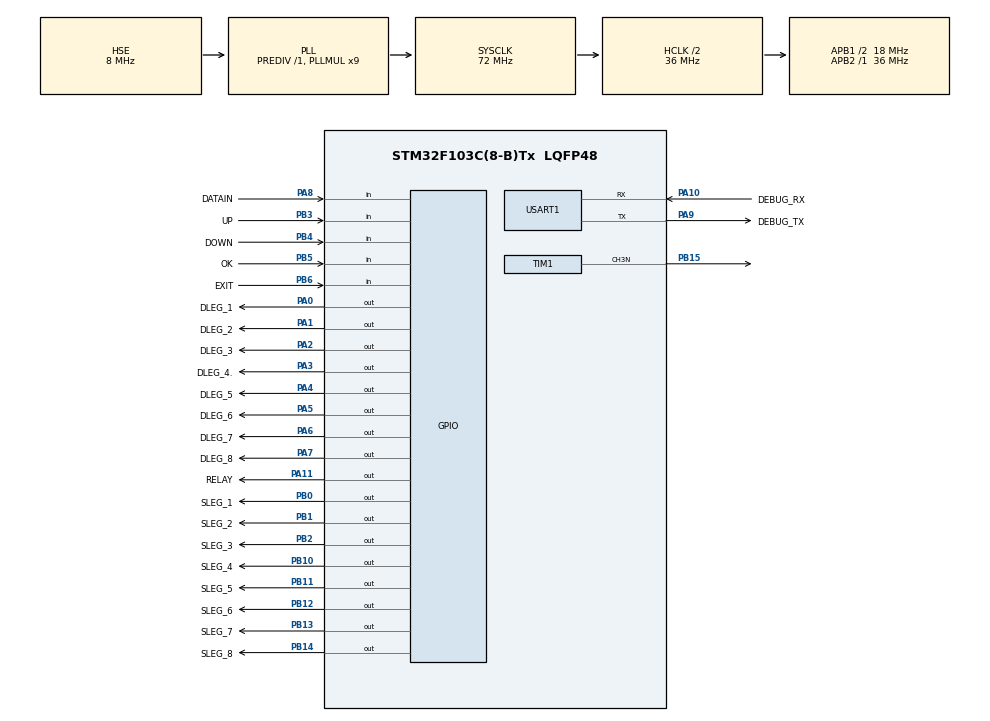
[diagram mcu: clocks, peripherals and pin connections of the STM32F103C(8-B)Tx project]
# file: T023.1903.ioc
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Mcu.Family=STM32F1
Mcu.Name=STM32F103C(8-B)Tx
Mcu.Package=LQFP48
NVIC.PriorityGroup=NVIC_PRIORITYGROUP_4
NVIC.TIM4_IRQn=true\:0\:0\:false\:false\:true\:true\:true
PA0-WKUP.GPIO_Label=DLEG_1
PA0-WKUP.Signal=GPIO_Output
PA1.GPIO_Label=DLEG_2
PA1.Signal=GPIO_Output
PA10.GPIO_Label=DEBUG_RX
PA10.Mode=Asynchronous
PA10.Signal=USART1_RX
PA11.GPIO_Label=RELAY
PA11.Signal=GPIO_Output
PA13.Mode=Serial_Wire
PA13.Signal=SYS_JTMS-SWDIO
PA14.Mode=Serial_Wire
PA14.Signal=SYS_JTCK-SWCLK
PA2.GPIO_Label=DLEG_3
PA2.Signal=GPIO_Output
PA3.GPIO_Label=DLEG_4.
PA3.Signal=GPIO_Output
PA4.GPIO_Label=DLEG_5
PA4.Signal=GPIO_Output
PA5.GPIO_Label=DLEG_6
PA5.Signal=GPIO_Output
PA6.GPIO_Label=DLEG_7
PA6.Signal=GPIO_Output
PA7.GPIO_Label=DLEG_8
PA7.Signal=GPIO_Output
PA8.GPIO_Label=DATAIN
PA8.Signal=GPIO_Input
PA9.GPIO_Label=DEBUG_TX
PA9.Mode=Asynchronous
PA9.Signal=USART1_TX
PB0.GPIO_Label=SLEG_1
PB0.Signal=GPIO_Output
PB1.GPIO_Label=SLEG_2
PB1.Signal=GPIO_Output
PB10.GPIO_Label=SLEG_4
PB10.Signal=GPIO_Output
PB11.GPIO_Label=SLEG_5
PB11.Signal=GPIO_Output
PB12.GPIO_Label=SLEG_6
PB12.Signal=GPIO_Output
PB13.GPIO_Label=SLEG_7
PB13.Signal=GPIO_Output
PB14.GPIO_Label=SLEG_8
PB14.Signal=GPIO_Output
PB15.Mode=PWM Generation3 CH3N
PB15.Signal=TIM1_CH3N
PB2.GPIO_Label=SLEG_3
PB2.Signal=GPIO_Output
PB3.GPIO_Label=UP
PB3.Signal=GPIO_Input
PB4.GPIO_Label=DOWN
PB4.Signal=GPIO_Input
PB5.GPIO_Label=OK
PB5.Signal=GPIO_Input
PB6.GPIO_Label=EXIT
PB6.Signal=GPIO_Input
PD0-OSC_IN.Mode=HSE-External-Oscillator
PD0-OSC_IN.Signal=RCC_OSC_IN
PD1-OSC_OUT.Mode=HSE-External-Oscillator
PD1-OSC_OUT.Signal=RCC_OSC_OUT
ProjectManager.HeapSize=0x200
ProjectManager.StackSize=0x400
ProjectManager.TargetToolchain=MDK-ARM V5
RCC.AHBCLKDivider=RCC_SYSCLK_DIV2
RCC.AHBFreq_Value=36000000
RCC.APB1CLKDivider=RCC_HCLK_DIV2
RCC.APB1Freq_Value=18000000
RCC.APB1TimFreq_Value=36000000
RCC.APB2Freq_Value=36000000
RCC.APB2TimFreq_Value=36000000
RCC.HCLKFreq_Value=36000000
RCC.PLLMUL=RCC_PLL_MUL9
RCC.PLLSourceVirtual=RCC_PLLSOURCE_HSE
RCC.SYSCLKFreq_VALUE=72000000
RCC.SYSCLKSource=RCC_SYSCLKSOURCE_PLLCLK
RCC.USBFreq_Value=72000000
TIM1.Channel-PWM\ Generation3\ CH3N=TIM_CHANNEL_3
TIM1.OCFastMode_PWM-PWM\ Generation3\ CH3N=TIM_OCFAST_ENABLE
TIM1.Period=999
TIM1.Prescaler=35
TIM4.Period=99
TIM4.Prescaler=179
USART1.VirtualMode=VM_ASYNC
VP_TIM1_VS_ClockSourceINT.Mode=Internal
VP_TIM4_VS_ClockSourceINT.Mode=Internal
board=custom

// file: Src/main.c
/* USER CODE BEGIN Header */
/**
  ******************************************************************************
  * @file           : main.c
  * @brief          : Main program body
  ******************************************************************************
  * @attention
  *
  * <h2><center>&copy; Copyright (c) 2019 STMicroelectronics.
  * All rights reserved.</center></h2>
  *
  * This software component is licensed by ST under BSD 3-Clause license,
  * the "License"; You may not use this file except in compliance with the
  * License. You may obtain a copy of the License at:
  *                        opensource.org/licenses/BSD-3-Clause
  *
  ******************************************************************************
  */
/* USER CODE END Header */

#include "main.h"
#include "tim.h"
#include "usart.h"
#include "gpio.h"

/* USER CODE BEGIN Includes */
#include "app.h"
/* USER CODE END Includes */

/* USER CODE BEGIN PV */
/* Private variables ---------------------------------------------------------*/

/* USER CODE END PV */

void SystemClock_Config(void);
/* USER CODE BEGIN PFP */
/* Private function prototypes -----------------------------------------------*/

/* USER CODE END PFP */

int main(void)
{

  /* MCU Configuration--------------------------------------------------------*/

  /* Reset of all peripherals, Initializes the Flash interface and the Systick. */
  HAL_Init();

  /* Configure the system clock */
  SystemClock_Config();

  /* Initialize all configured peripherals */
  MX_GPIO_Init();
  MX_TIM1_Init();
  MX_USART1_UART_Init();
  MX_TIM4_Init();
  /* USER CODE BEGIN 2 */
  App_Init();
  /* USER CODE END 2 */

  /* Infinite loop */
  while (1)
  {

    /* USER CODE BEGIN 3 */
    App_Step();
  }
  /* USER CODE END 3 */
}

void SystemClock_Config(void)
{
  RCC_OscInitTypeDef RCC_OscInitStruct = {0};
  RCC_ClkInitTypeDef RCC_ClkInitStruct = {0};

  /** Initializes the CPU, AHB and APB busses clocks
  */
  RCC_OscInitStruct.OscillatorType = RCC_OSCILLATORTYPE_HSE;
  RCC_OscInitStruct.HSEState = RCC_HSE_ON;
  RCC_OscInitStruct.HSEPredivValue = RCC_HSE_PREDIV_DIV1;
  RCC_OscInitStruct.HSIState = RCC_HSI_ON;
  RCC_OscInitStruct.PLL.PLLState = RCC_PLL_ON;
  RCC_OscInitStruct.PLL.PLLSource = RCC_PLLSOURCE_HSE;
  RCC_OscInitStruct.PLL.PLLMUL = RCC_PLL_MUL9;
  if (HAL_RCC_OscConfig(&RCC_OscInitStruct) != HAL_OK)
  {
    Error_Handler();
  }
  /** Initializes the CPU, AHB and APB busses clocks
  */
  RCC_ClkInitStruct.ClockType = RCC_CLOCKTYPE_HCLK|RCC_CLOCKTYPE_SYSCLK
                              |RCC_CLOCKTYPE_PCLK1|RCC_CLOCKTYPE_PCLK2;
  RCC_ClkInitStruct.SYSCLKSource = RCC_SYSCLKSOURCE_PLLCLK;
  RCC_ClkInitStruct.AHBCLKDivider = RCC_SYSCLK_DIV2;
  RCC_ClkInitStruct.APB1CLKDivider = RCC_HCLK_DIV2;
  RCC_ClkInitStruct.APB2CLKDivider = RCC_HCLK_DIV1;

  if (HAL_RCC_ClockConfig(&RCC_ClkInitStruct, FLASH_LATENCY_2) != HAL_OK)
  {
    Error_Handler();
  }
}

void Error_Handler(void)
{
  while(1)
  {
  }
}

/************************ (C) COPYRIGHT STMicroelectronics *****END OF FILE****/
